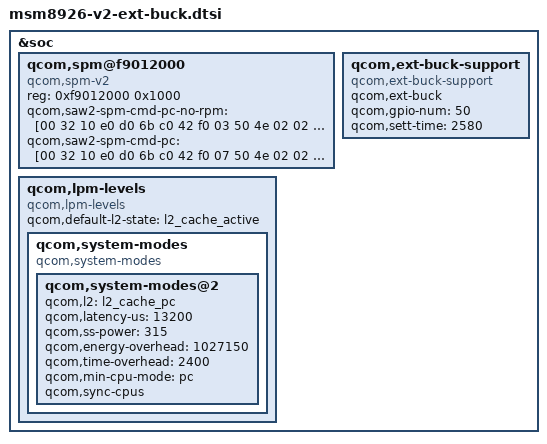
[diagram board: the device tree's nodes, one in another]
/* Copyright (c) 2013-2014, The Linux Foundation. All rights reserved.
 *
 * This program is free software; you can redistribute it and/or modify
 * it under the terms of the GNU General Public License version 2 and
 * only version 2 as published by the Free Software Foundation.
 *
 * This program is distributed in the hope that it will be useful,
 * but WITHOUT ANY WARRANTY; without even the implied warranty of
 * MERCHANTABILITY or FITNESS FOR A PARTICULAR PURPOSE.  See the
 * GNU General Public License for more details.
 */

/include/ "msm8926-v2.dtsi"

&soc {
	qcom,spm@f9012000 {
		compatible = "qcom,spm-v2";
		#address-cells = <1>;
		#size-cells = <1>;
		reg = <0xf9012000 0x1000>;
		qcom,saw2-spm-cmd-pc-no-rpm = [00 32 10 e0 d0 6b c0 42 f0
				03 50 4e 02 02 c0 d0 12 e0 6b 02 32
				50 f0 0f];
		qcom,saw2-spm-cmd-pc = [00 32 10 e0 d0 6b c0 42 f0
				07 50 4e 02 02 c0 d0 12 e0 6b 02 32
				50 f0 0f];
	};

	qcom,lpm-levels {
		compatible = "qcom,lpm-levels";
		qcom,default-l2-state = "l2_cache_active";
		#address-cells = <1>;
		#size-cells = <0>;
		qcom,system-modes {
			compatible = "qcom,system-modes";
			qcom,system-modes@2 {
				qcom,l2 = "l2_cache_pc";
				qcom,latency-us = <13200>;
				qcom,ss-power = <315>;
				qcom,energy-overhead = <1027150>;
				qcom,time-overhead = <2400>;
				qcom,min-cpu-mode= "pc";
				qcom,sync-cpus;
			};
		};
	};

	qcom,ext-buck-support {
		compatible = "qcom,ext-buck-support";
		qcom,ext-buck;
		qcom,gpio-num = <50>;
		qcom,sett-time = <2580>;/* ~500us caliculated interms of QTIMER(19.2MHz) ticks */
	};
};
